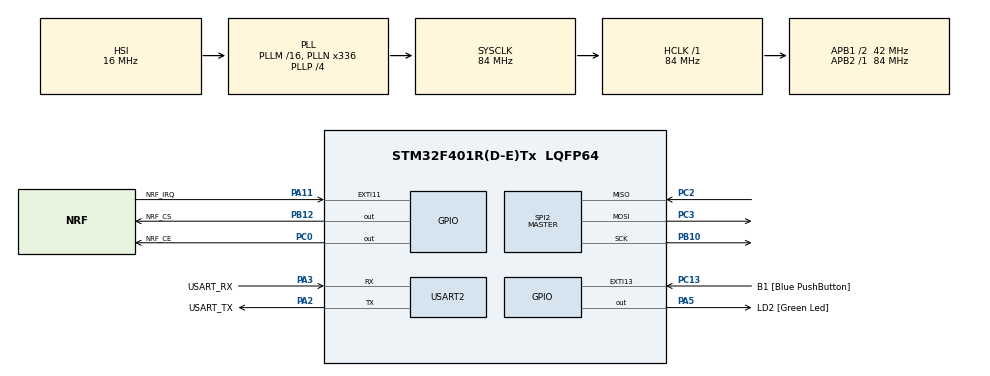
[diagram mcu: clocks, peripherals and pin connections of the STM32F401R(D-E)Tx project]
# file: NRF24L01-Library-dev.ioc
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Dma.Request0=USART2_RX
Dma.USART2_RX.0.Direction=DMA_PERIPH_TO_MEMORY
Dma.USART2_RX.0.FIFOMode=DMA_FIFOMODE_ENABLE
Dma.USART2_RX.0.FIFOThreshold=DMA_FIFO_THRESHOLD_FULL
Dma.USART2_RX.0.Instance=DMA1_Stream5
Dma.USART2_RX.0.MemBurst=DMA_MBURST_SINGLE
Dma.USART2_RX.0.MemDataAlignment=DMA_MDATAALIGN_BYTE
Dma.USART2_RX.0.MemInc=DMA_MINC_ENABLE
Dma.USART2_RX.0.Mode=DMA_CIRCULAR
Dma.USART2_RX.0.PeriphBurst=DMA_PBURST_SINGLE
Dma.USART2_RX.0.PeriphDataAlignment=DMA_PDATAALIGN_BYTE
Dma.USART2_RX.0.PeriphInc=DMA_PINC_DISABLE
Dma.USART2_RX.0.Priority=DMA_PRIORITY_MEDIUM
Mcu.Family=STM32F4
Mcu.Name=STM32F401R(D-E)Tx
Mcu.Package=LQFP64
NVIC.DMA1_Stream5_IRQn=true\:0\:0\:false\:false\:true\:false
NVIC.EXTI15_10_IRQn=true\:0\:0\:false\:false\:true\:true
NVIC.PriorityGroup=NVIC_PRIORITYGROUP_0
NVIC.SPI2_IRQn=true\:0\:0\:false\:false\:true\:true
NVIC.USART2_IRQn=true\:0\:0\:false\:false\:true\:true
PA11.GPIO_Label=NRF_IRQ
PA11.GPIO_ModeDefaultEXTI=GPIO_MODE_IT_FALLING
PA11.GPIO_PuPd=GPIO_PULLUP
PA11.Signal=GPXTI11
PA13.GPIO_Label=TMS
PA13.Mode=Serial_Wire
PA13.Signal=SYS_JTMS-SWDIO
PA14.GPIO_Label=TCK
PA14.Mode=Serial_Wire
PA14.Signal=SYS_JTCK-SWCLK
PA2.GPIO_Label=USART_TX
PA2.GPIO_Mode=GPIO_MODE_AF_PP
PA2.GPIO_PuPd=GPIO_NOPULL
PA2.GPIO_Speed=GPIO_SPEED_FREQ_LOW
PA2.Mode=Asynchronous
PA2.Signal=USART2_TX
PA3.GPIO_Label=USART_RX
PA3.GPIO_Mode=GPIO_MODE_AF_PP
PA3.GPIO_PuPd=GPIO_NOPULL
PA3.GPIO_Speed=GPIO_SPEED_FREQ_LOW
PA3.Mode=Asynchronous
PA3.Signal=USART2_RX
PA5.GPIO_Label=LD2 [Green Led]
PA5.GPIO_Mode=GPIO_MODE_OUTPUT_PP
PA5.GPIO_PuPd=GPIO_NOPULL
PA5.GPIO_Speed=GPIO_SPEED_FREQ_LOW
PA5.Signal=GPIO_Output
PB10.GPIO_PuPd=GPIO_NOPULL
PB10.Mode=Full_Duplex_Master
PB10.Signal=SPI2_SCK
PB12.GPIO_Label=NRF_CS
PB12.GPIO_PuPd=GPIO_PULLUP
PB12.GPIO_Speed=GPIO_SPEED_FREQ_VERY_HIGH
PB12.PinState=GPIO_PIN_SET
PB12.Signal=GPIO_Output
PB3.GPIO_Label=SWO
PB3.Signal=SYS_JTDO-SWO
PC0.GPIO_Label=NRF_CE
PC0.GPIO_PuPd=GPIO_PULLDOWN
PC0.GPIO_Speed=GPIO_SPEED_FREQ_VERY_HIGH
PC0.Signal=GPIO_Output
PC13-ANTI_TAMP.GPIO_Label=B1 [Blue PushButton]
PC13-ANTI_TAMP.GPIO_ModeDefaultEXTI=GPIO_MODE_IT_FALLING
PC13-ANTI_TAMP.GPIO_PuPd=GPIO_NOPULL
PC13-ANTI_TAMP.Signal=GPXTI13
PC14-OSC32_IN.Mode=LSE-External-Oscillator
PC14-OSC32_IN.Signal=RCC_OSC32_IN
PC15-OSC32_OUT.Mode=LSE-External-Oscillator
PC15-OSC32_OUT.Signal=RCC_OSC32_OUT
PC2.GPIO_PuPd=GPIO_NOPULL
PC2.Mode=Full_Duplex_Master
PC2.Signal=SPI2_MISO
PC3.GPIO_PuPd=GPIO_NOPULL
PC3.Mode=Full_Duplex_Master
PC3.Signal=SPI2_MOSI
PH0\ -\ OSC_IN.Mode=HSE-External-Clock-Source
PH0\ -\ OSC_IN.Signal=RCC_OSC_IN
PH1\ -\ OSC_OUT.Mode=HSE-External-Clock-Source
PH1\ -\ OSC_OUT.Signal=RCC_OSC_OUT
ProjectManager.HeapSize=0x200
ProjectManager.StackSize=0x400
ProjectManager.TargetToolchain=MDK-ARM V5
RCC.48MHZClocksFreq_Value=48000000
RCC.AHBFreq_Value=84000000
RCC.APB1CLKDivider=RCC_HCLK_DIV2
RCC.APB1Freq_Value=42000000
RCC.APB1TimFreq_Value=84000000
RCC.APB2Freq_Value=84000000
RCC.APB2TimFreq_Value=84000000
RCC.CortexFreq_Value=84000000
RCC.HCLKFreq_Value=84000000
RCC.HSE_VALUE=8000000
RCC.HSI_VALUE=16000000
RCC.PLLN=336
RCC.PLLP=RCC_PLLP_DIV4
RCC.PLLQ=7
RCC.SYSCLKFreq_VALUE=84000000
RCC.SYSCLKSource=RCC_SYSCLKSOURCE_PLLCLK
RCC.VCOOutputFreq_Value=336000000
SPI2.BaudRatePrescaler=SPI_BAUDRATEPRESCALER_128
SPI2.CLKPolarity=SPI_POLARITY_LOW
SPI2.CRCCalculation=SPI_CRCCALCULATION_DISABLE
SPI2.Direction=SPI_DIRECTION_2LINES
SPI2.Mode=SPI_MODE_MASTER
SPI2.TIMode=SPI_TIMODE_DISABLE
SPI2.VirtualNSS=VM_NSSHARD
SPI2.VirtualType=VM_MASTER
USART2.VirtualMode=VM_ASYNC
board=NUCLEO-F401RE

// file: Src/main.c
/**
  ******************************************************************************
  * @file           : main.c
  * @brief          : Main program body
  ******************************************************************************
  ** This notice applies to any and all portions of this file
  * that are not between comment pairs USER CODE BEGIN and
  * USER CODE END. Other portions of this file, whether
  * inserted by the user or by software development tools
  * are owned by their respective copyright owners.
  *
  * COPYRIGHT(c) 2019 STMicroelectronics
  *
  * Redistribution and use in source and binary forms, with or without modification,
  * are permitted provided that the following conditions are met:
  *   1. Redistributions of source code must retain the above copyright notice,
  *      this list of conditions and the following disclaimer.
  *   2. Redistributions in binary form must reproduce the above copyright notice,
  *      this list of conditions and the following disclaimer in the documentation
  *      and/or other materials provided with the distribution.
  *   3. Neither the name of STMicroelectronics nor the names of its contributors
  *      may be used to endorse or promote products derived from this software
  *      without specific prior written permission.
  *
  * THIS SOFTWARE IS PROVIDED BY THE COPYRIGHT HOLDERS AND CONTRIBUTORS "AS IS"
  * AND ANY EXPRESS OR IMPLIED WARRANTIES, INCLUDING, BUT NOT LIMITED TO, THE
  * IMPLIED WARRANTIES OF MERCHANTABILITY AND FITNESS FOR A PARTICULAR PURPOSE ARE
  * DISCLAIMED. IN NO EVENT SHALL THE COPYRIGHT HOLDER OR CONTRIBUTORS BE LIABLE
  * FOR ANY DIRECT, INDIRECT, INCIDENTAL, SPECIAL, EXEMPLARY, OR CONSEQUENTIAL
  * DAMAGES (INCLUDING, BUT NOT LIMITED TO, PROCUREMENT OF SUBSTITUTE GOODS OR
  * SERVICES; LOSS OF USE, DATA, OR PROFITS; OR BUSINESS INTERRUPTION) HOWEVER
  * CAUSED AND ON ANY THEORY OF LIABILITY, WHETHER IN CONTRACT, STRICT LIABILITY,
  * OR TORT (INCLUDING NEGLIGENCE OR OTHERWISE) ARISING IN ANY WAY OUT OF THE USE
  * OF THIS SOFTWARE, EVEN IF ADVISED OF THE POSSIBILITY OF SUCH DAMAGE.
  *
  ******************************************************************************
  */
#include "main.h"
#include "stm32f4xx_hal.h"
#include "dma.h"
#include "spi.h"
#include "usart.h"
#include "gpio.h"

/* USER CODE BEGIN Includes */
#include "NRF24L01P_H.h"
/* USER CODE END Includes */

/* USER CODE BEGIN PV */
/* Private variables ---------------------------------------------------------*/
NRF24L01P_ExTypeDef		nrf;

uint8_t							tmp_reg_1 			= 0;
uint8_t							tmp_stat_1 			= 0;
uint8_t							tmp_msg_1[32] 	= "";

/* USER CODE END PV */

void SystemClock_Config(void);

/* USER CODE BEGIN PFP */
/* Private function prototypes -----------------------------------------------*/

/* USER CODE END PFP */

int main(void)
{

  /* MCU Configuration----------------------------------------------------------*/

  /* Reset of all peripherals, Initializes the Flash interface and the Systick. */
  HAL_Init();

  /* Configure the system clock */
  SystemClock_Config();

  /* Initialize all configured peripherals */
  MX_GPIO_Init();
  MX_DMA_Init();
  MX_USART2_UART_Init();
  MX_SPI2_Init();
  /* USER CODE BEGIN 2 */

	/* Test code for NRF24L01P.h/.c

	nrf.hspi = &hspi2;
	nrf.spi_cs_port = NRF_CS_GPIO_Port;
	nrf.spi_cs_pin  = NRF_CS_Pin;

	HAL_Delay(2000);
	HAL_UART_Transmit(&huart2, (uint8_t*)"Hello!\n", 7, HAL_MAX_DELAY);

	// Read Config Register and show on UART
	if( NRF_EX_Read_Reg( &nrf, NRF_REG_CONFIG, 1, &tmp_reg_1, &tmp_stat_1) == HAL_OK)
	{
		HAL_UART_Transmit(&huart2, (uint8_t*)"00001!\n", 7, HAL_MAX_DELAY);
	}

	sprintf((char*)tmp_msg_1, "Init => %4d\n", tmp_reg_1);
	HAL_UART_Transmit(&huart2, tmp_msg_1, 13, HAL_MAX_DELAY);

	// Toggle PTx/PRx bit in config register
	tmp_reg_1 ^= 0x01U;

	// Write Config Register
	if( NRF_EX_Write_Reg(&nrf, NRF_REG_CONFIG, 1, &tmp_reg_1, &tmp_stat_1) == HAL_OK )
	{
		HAL_UART_Transmit(&huart2, (uint8_t*)"00002!\n", 7, HAL_MAX_DELAY);
	}

	// Read Config Register and show on UART + Show STAT Reg
	if( NRF_EX_Read_Reg( &nrf, NRF_REG_CONFIG, 1, &tmp_reg_1, &tmp_stat_1) == HAL_OK )
	{
		HAL_UART_Transmit(&huart2, (uint8_t*)"00003!\n", 7, HAL_MAX_DELAY);
	}

	sprintf((char*)tmp_msg_1, "Final => %4d\n", tmp_reg_1);
	HAL_UART_Transmit(&huart2, tmp_msg_1, 14, HAL_MAX_DELAY);

	sprintf((char*)tmp_msg_1, "Stat  => %4d\n", tmp_stat_1);
	HAL_UART_Transmit(&huart2, tmp_msg_1, 14, HAL_MAX_DELAY);

	*/

	/* Test the '~' and '!' operators

	tmp_reg_1 = ~(0x00);
	sprintf((char*)tmp_msg_1, "test~ => %4d\n", tmp_reg_1);
	HAL_UART_Transmit(&huart2, tmp_msg_1, 14, HAL_MAX_DELAY);

	tmp_reg_1 = !(0x00);
	sprintf((char*)tmp_msg_1, "test! => %4d\n", tmp_reg_1);
	HAL_UART_Transmit(&huart2, tmp_msg_1, 14, HAL_MAX_DELAY);

	*/

  /* USER CODE END 2 */

  /* Infinite loop */
  while (1)
  {

  }

}

void SystemClock_Config(void)
{

  RCC_OscInitTypeDef RCC_OscInitStruct;
  RCC_ClkInitTypeDef RCC_ClkInitStruct;

    /**Configure the main internal regulator output voltage
    */
  __HAL_RCC_PWR_CLK_ENABLE();

  __HAL_PWR_VOLTAGESCALING_CONFIG(PWR_REGULATOR_VOLTAGE_SCALE2);

    /**Initializes the CPU, AHB and APB busses clocks
    */
  RCC_OscInitStruct.OscillatorType = RCC_OSCILLATORTYPE_HSI;
  RCC_OscInitStruct.HSIState = RCC_HSI_ON;
  RCC_OscInitStruct.HSICalibrationValue = 16;
  RCC_OscInitStruct.PLL.PLLState = RCC_PLL_ON;
  RCC_OscInitStruct.PLL.PLLSource = RCC_PLLSOURCE_HSI;
  RCC_OscInitStruct.PLL.PLLM = 16;
  RCC_OscInitStruct.PLL.PLLN = 336;
  RCC_OscInitStruct.PLL.PLLP = RCC_PLLP_DIV4;
  RCC_OscInitStruct.PLL.PLLQ = 7;
  if (HAL_RCC_OscConfig(&RCC_OscInitStruct) != HAL_OK)
  {
    _Error_Handler(__FILE__, __LINE__);
  }

    /**Initializes the CPU, AHB and APB busses clocks
    */
  RCC_ClkInitStruct.ClockType = RCC_CLOCKTYPE_HCLK|RCC_CLOCKTYPE_SYSCLK
                              |RCC_CLOCKTYPE_PCLK1|RCC_CLOCKTYPE_PCLK2;
  RCC_ClkInitStruct.SYSCLKSource = RCC_SYSCLKSOURCE_PLLCLK;
  RCC_ClkInitStruct.AHBCLKDivider = RCC_SYSCLK_DIV1;
  RCC_ClkInitStruct.APB1CLKDivider = RCC_HCLK_DIV2;
  RCC_ClkInitStruct.APB2CLKDivider = RCC_HCLK_DIV1;

  if (HAL_RCC_ClockConfig(&RCC_ClkInitStruct, FLASH_LATENCY_2) != HAL_OK)
  {
    _Error_Handler(__FILE__, __LINE__);
  }

    /**Configure the Systick interrupt time
    */
  HAL_SYSTICK_Config(HAL_RCC_GetHCLKFreq()/1000);

    /**Configure the Systick
    */
  HAL_SYSTICK_CLKSourceConfig(SYSTICK_CLKSOURCE_HCLK);

  /* SysTick_IRQn interrupt configuration */
  HAL_NVIC_SetPriority(SysTick_IRQn, 0, 0);
}

void _Error_Handler(char *file, int line)
{
  while(1)
  {
  }
}

/************************ (C) COPYRIGHT STMicroelectronics *****END OF FILE****/
